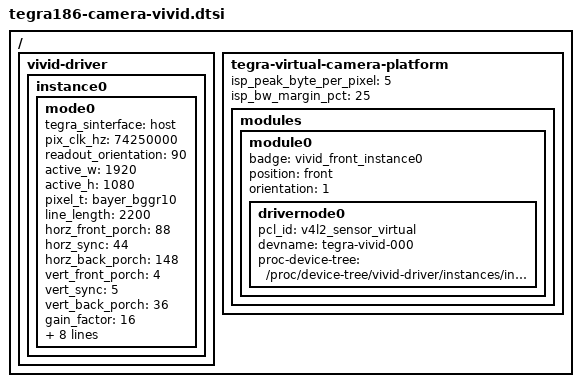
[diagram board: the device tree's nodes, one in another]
/*
 * Copyright (c) 2017-2018, NVIDIA CORPORATION.  All rights reserved.
 *
 * This program is free software; you can redistribute it and/or modify
 * it under the terms of the GNU General Public License as published by
 * the Free Software Foundation; either version 2 of the License, or
 * (at your option) any later version.
 *
 * This program is distributed in the hope that it will be useful, but WITHOUT
 * ANY WARRANTY; without even the implied warranty of MERCHANTABILITY or
 * FITNESS FOR A PARTICULAR PURPOSE.  See the GNU General Public License for
 * more details.
 *
 * You should have received a copy of the GNU General Public License
 * along with this program.  If not, see <http://www.gnu.org/licenses/>.
 */

/ {
	vivid-driver {
		instance0 {
			/**
			* ==== Modes ====
			* A modeX node is required to support v4l2 driver
			* implementation with NVIDIA camera software stack
			*
			* == Signal properties ==
			*
			* tegra_sinterface = "";
			* CSI Serial interface connected to tegra
			* Incase of virtual HW devices, use virtual
			* For SW emulated devices, use host
			*
			* pix_clk_hz = "";
			* Sensor pixel clock used for calculations like exposure and framerate
			*
			* readout_orientation = "0";
			* Based on camera module orientation.
			* Only change readout_orientation if you specifically
			* Program a different readout order for this mode
			*
			* == Image format Properties ==
			*
			* active_w = "";
			* Pixel active region width
			*
			* active_h = "";
			* Pixel active region height
			*
			* pixel_t = "";
			* The sensor readout pixel pattern
			*
			* line_length = "";
			* Pixel line length (width) for sensor mode.
			* For vivid HDMI source, this is total width calculated from dvtimings
			* This is used to calibrate features in our camera stack.
			*
			*
			* == DV Timings ==
			*
			* horz_front_proch = "";
			* Horizontal front porch in pixels
			*
			* horz_sync = "";
			* Horizontal sync length in pixels
			*
			* horz_back_porch="";
			* Horizontal back porch in pixels
			*
			* vert_front_proch = "";
			* Vertical front porch in pixels
			*
			* vert_sync = "";
			* Vertical sync length in pixels
			*
			* vert_back_porch="";
			* Vertical back porch in pixels
			*
			* == Source Control Settings ==
			*
			* gain_factor = "";
			* Gain factor used to convert fixed point integer to float
			* Gain range [min_gain/gain_factor, max_gain/gain_factor]
			*
			* framerate_factor = "";
			* Framerate factor used to convert fixed point integer to float
			* Framerate range [min_framerate/framerate_factor, max_framerate/framerate_factor]
			*
			* min_gain_val = ""; (floor to 6 decimal places)
			* max_gain_val = ""; (floor to 6 decimal places)
			* Gain limits for mode
			*
			* min_exp_time = ""; (ceil to integer)
			* max_exp_time = ""; (ceil to integer)
			* Exposure Time limits for mode (us)
			*
			* min_framerate = "";
			* max_framerate = "";
			* Framerate limits for mode (fps)
			*
			* embedded_metadata_height = "";
			* Sensor embedded metadata height in units of rows.
			* If sensor does not support embedded metadata value should be 0.
			*/
			mode0 { // VIVID_1920x1080
				tegra_sinterface = "host";
				pix_clk_hz = "74250000";
				readout_orientation = "90";

				active_w = "1920";
				active_h = "1080";
				pixel_t = "bayer_bggr10";
				line_length = "2200";

				horz_front_porch = "88";
				horz_sync = "44";
				horz_back_porch = "148";
				vert_front_porch = "4";
				vert_sync = "5";
				vert_back_porch = "36";

				gain_factor = "16";
				framerate_factor = "1";
				min_gain_val = "1";
				max_gain_val = "256";
				min_exp_time = "34";
				max_exp_time = "999994";
				min_framerate = "1";
				max_framerate = "30";
				embedded_metadata_height = "1";
			};
		};
	};

	tegra-virtual-camera-platform {
		/**
		* Physical settings to calculate max ISO BW
		*
		*
		* max_pixel_rate = <>;
		* Max pixel rate in Kpixel/s for the ISP ISO case
		*
		* isp_peak_byte_per_pixel = <>;
		* Max byte per pixel for the ISP ISO case
		*
		* isp_bw_margin_pct = <>;
		* Isp bandwidth margin in percentage
		*/
		isp_peak_byte_per_pixel = <5>;
		isp_bw_margin_pct = <25>;

		/**
		* The general guideline for naming badge_info contains 3 parts, and is as follows,
		* The first part is to represent source driver name
		* The second part contains the position of the module, ex. “rear” or “front”
		* The third part contains the instance number for vivid
		*/
		modules {
			module0 {
				badge = "vivid_front_instance0";
				position = "front";
				orientation = "1";
				drivernode0 {
					/* Declare PCL support driver (classically known as guid)  */
					pcl_id = "v4l2_sensor_virtual";
					/* Driver v4l2 device name */
					devname = "tegra-vivid-000";
					/* Declare the device-tree hierarchy to driver instance */
					proc-device-tree = "/proc/device-tree/vivid-driver/instances/instance0";
				};
			};
		};
	};
};
